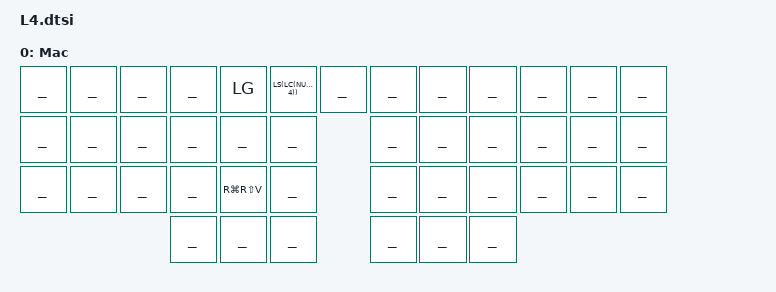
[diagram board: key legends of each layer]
/ {
	keymap {
		compatible = "zmk,keymap";

		shortcuts {
			label = "Mac";
			bindings = <
		// ╭───────────────┬───────────────┬───────────────┬───────────────┬───────────────┬───────────────╮   ╭───────────────┬───────────────┬───────────────┬───────────────┬───────────────┬───────────────╮
		//  0               1               2               3               4               5                   6               7               8               9               10              11
		 	___              ___            ___              ___            &kp LG(LS(LC(NUMBER_4)))  ___       ___              ___            ___              ___            ___              ___
		// ├───────────────├───────────────┼───────────────┼───────────────┼───────────────┼───────────────┤   ├───────────────├───────────────┼───────────────┼───────────────┼───────────────┼───────────────┤
		//  12              13              14              15              16              17                  18              19              20              21              22              23
		 	___              ___            ___              ___            ___              ___                ___              ___            ___              ___            ___              ___
		// ├───────────────├───────────────┼───────────────┼───────────────┼───────────────┼───────────────┤   ├───────────────├───────────────┼───────────────┼───────────────┼───────────────┼───────────────┤
		//  24              25              26              27              28              29                  30              31              32              33              34              35
		    ___              ___            ___              ___           &kp RG(RS(V))   ___                  ___              ___            ___              ___            ___              ___
		// ╰───────────────┴───────────────┴───────────────┼───────────────┼───────────────┼───────────────┤   ├───────────────├───────────────┼───────────────┼───────────────┴───────────────┴───────────────╯
		//                                                  36              37              38                  39              40              41
															___             ___             ___	               	___             ___             ___
		//                                                 ╰───────────────┴───────────────┴───────────────╯   ╰───────────────┴───────────────┴───────────────╯
			>;
		};

	};
};
